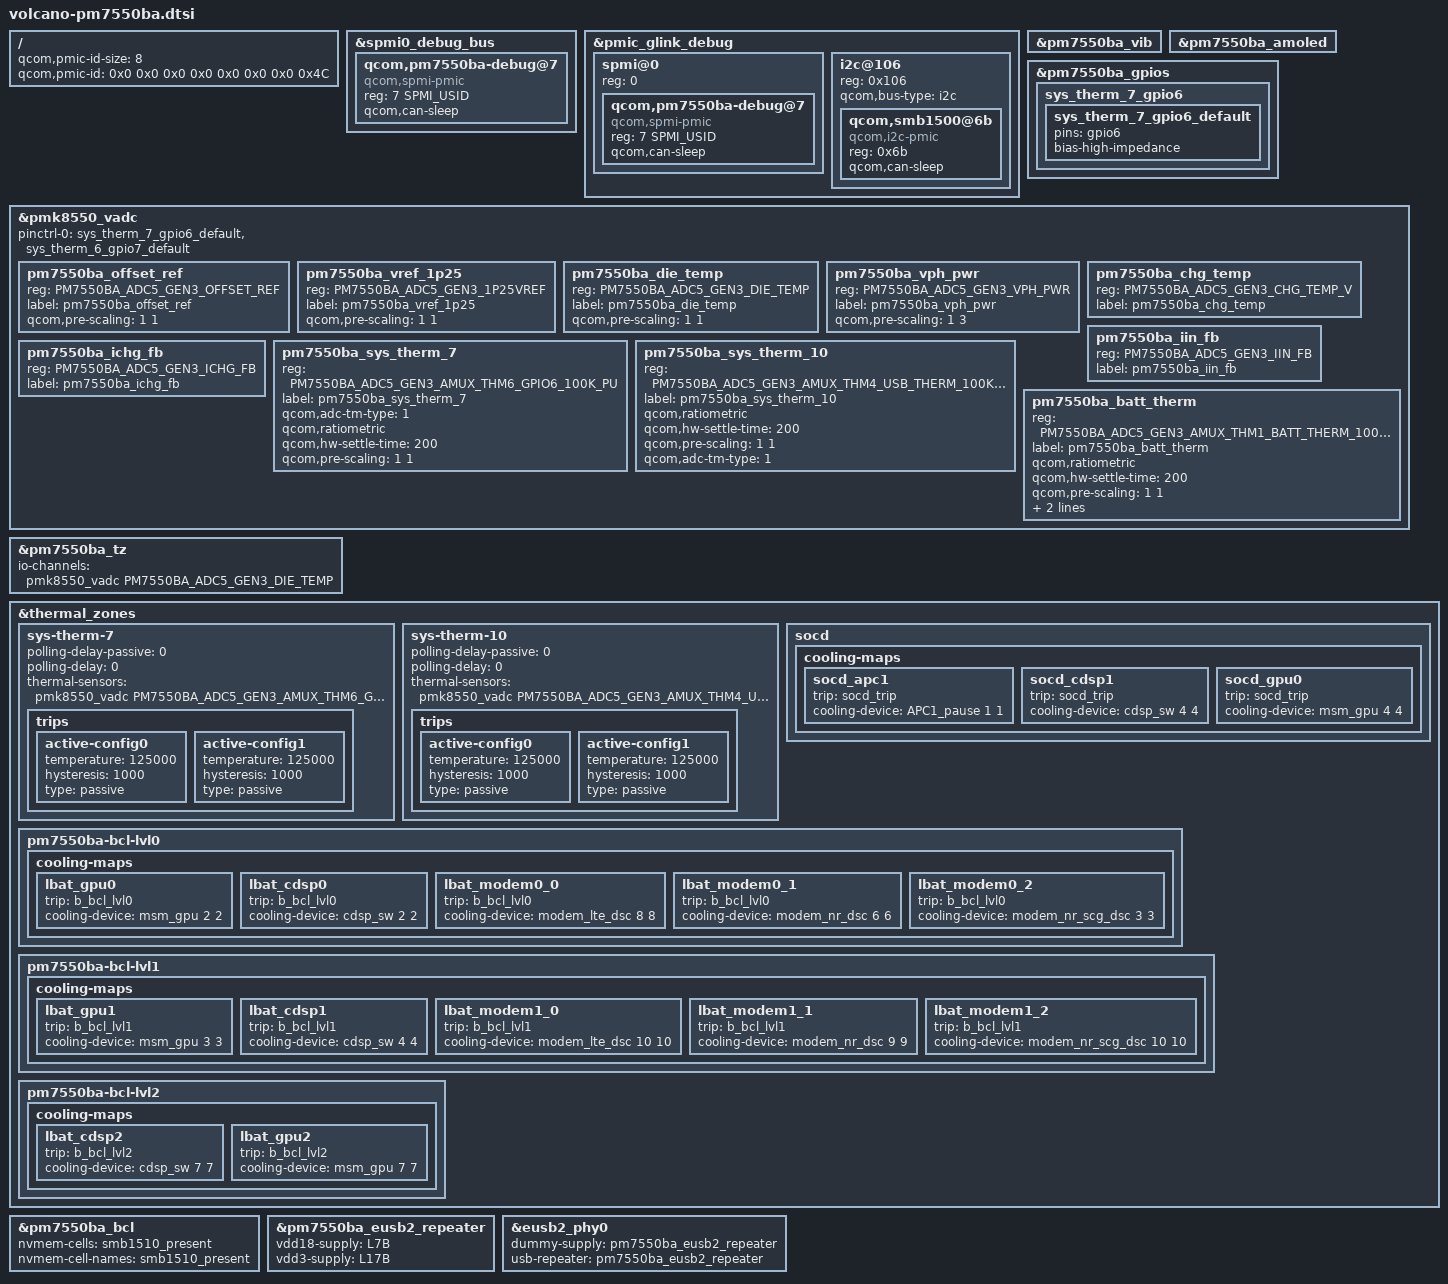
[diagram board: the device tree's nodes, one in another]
#include "pm7550ba.dtsi"
#include <dt-bindings/iio/qcom,spmi-vadc.h>
#include <dt-bindings/iio/qcom,spmi-adc5-gen3-pm7550ba.h>
#include <dt-bindings/spmi/spmi.h>

/ {
	qcom,pmic-id-size = <8>;
	qcom,pmic-id = <0x0 0x0 0x0 0x0 0x0 0x0 0x0 0x4C>;
};

&spmi0_debug_bus {
	qcom,pm7550ba-debug@7 {
		compatible = "qcom,spmi-pmic";
		reg = <7 SPMI_USID>;
		#address-cells = <2>;
		#size-cells = <0>;
		qcom,can-sleep;
	};
};

&pmic_glink_debug {
	/* Primary SPMI bus */
	spmi@0 {
		reg = <0>;
		#address-cells = <2>;
		#size-cells = <0>;

		qcom,pm7550ba-debug@7 {
			compatible = "qcom,spmi-pmic";
			reg = <7 SPMI_USID>;
			qcom,can-sleep;
		};
	};

	i2c@106 {
		reg = <0x106>;  /* I2C instance 6 in ADSP for SE7 */
		#address-cells = <1>;
		#size-cells = <0>;
		qcom,bus-type = "i2c";

		qcom,smb1500@6b {
			compatible = "qcom,i2c-pmic";
			reg = <0x6b>;
			qcom,can-sleep;
		};
	};
};

&pm7550ba_vib {
	status = "okay";
};

&pm7550ba_amoled {
	status = "okay";
};

&pm7550ba_gpios {
	sys_therm_7_gpio6 {
		sys_therm_7_gpio6_default: sys_therm_7_gpio6_default {
			pins = "gpio6";
			bias-high-impedance;
		};
	};
};

&pmk8550_vadc {
	pinctrl-0 = <&sys_therm_7_gpio6_default &sys_therm_6_gpio7_default>;
	pinctrl-names = "default";

	/* PM7550BA Channel nodes */
	pm7550ba_offset_ref {
		reg = <PM7550BA_ADC5_GEN3_OFFSET_REF>;
		label = "pm7550ba_offset_ref";
		qcom,pre-scaling = <1 1>;
	};

	pm7550ba_vref_1p25 {
		reg = <PM7550BA_ADC5_GEN3_1P25VREF>;
		label = "pm7550ba_vref_1p25";
		qcom,pre-scaling = <1 1>;
	};

	pm7550ba_die_temp {
		reg = <PM7550BA_ADC5_GEN3_DIE_TEMP>;
		label = "pm7550ba_die_temp";
		qcom,pre-scaling = <1 1>;
	};

	pm7550ba_vph_pwr {
		reg = <PM7550BA_ADC5_GEN3_VPH_PWR>;
		label = "pm7550ba_vph_pwr";
		qcom,pre-scaling = <1 3>;
	};

	pm7550ba_chg_temp {
		reg = <PM7550BA_ADC5_GEN3_CHG_TEMP_V>;
		label = "pm7550ba_chg_temp";
	};

	pm7550ba_iin_fb {
		reg = <PM7550BA_ADC5_GEN3_IIN_FB>;
		label = "pm7550ba_iin_fb";
	};

	pm7550ba_ichg_fb {
		reg = <PM7550BA_ADC5_GEN3_ICHG_FB>;
		label = "pm7550ba_ichg_fb";
	};

	pm7550ba_sys_therm_7 {
		reg = <PM7550BA_ADC5_GEN3_AMUX_THM6_GPIO6_100K_PU>;
		label = "pm7550ba_sys_therm_7";
		qcom,adc-tm-type = <1>;
		qcom,ratiometric;
		qcom,hw-settle-time = <200>;
		qcom,pre-scaling = <1 1>;
	};

	pm7550ba_sys_therm_10 {
		reg = <PM7550BA_ADC5_GEN3_AMUX_THM4_USB_THERM_100K_PU>;
		label = "pm7550ba_sys_therm_10";
		qcom,ratiometric;
		qcom,hw-settle-time = <200>;
		qcom,pre-scaling = <1 1>;
		qcom,adc-tm-type = <1>;

	};

	pm7550ba_batt_therm {
		reg = <PM7550BA_ADC5_GEN3_AMUX_THM1_BATT_THERM_100K_PU>;
		label = "pm7550ba_batt_therm";
		qcom,ratiometric;
		qcom,hw-settle-time = <200>;
		qcom,pre-scaling = <1 1>;
		qcom,scale-fn-type = <ADC_SCALE_HW_CALIB_PM5_GEN3_BATT_THERM_100K>;
	};

};

&pm7550ba_tz {
	io-channels = <&pmk8550_vadc PM7550BA_ADC5_GEN3_DIE_TEMP>;
	io-channel-names = "thermal";
};

&thermal_zones {
	sys-therm-7 {
		polling-delay-passive = <0>;
		polling-delay = <0>;
		thermal-sensors = <&pmk8550_vadc PM7550BA_ADC5_GEN3_AMUX_THM6_GPIO6_100K_PU>;
		trips {
			active-config0 {
				temperature = <125000>;
				hysteresis = <1000>;
				type = "passive";
			};

			active-config1 {
				temperature = <125000>;
				hysteresis = <1000>;
				type = "passive";
			};
		};
	};

	sys-therm-10 {
		polling-delay-passive = <0>;
		polling-delay = <0>;
		thermal-sensors = <&pmk8550_vadc PM7550BA_ADC5_GEN3_AMUX_THM4_USB_THERM_100K_PU>;
		trips {
			active-config0 {
				temperature = <125000>;
				hysteresis = <1000>;
				type = "passive";
			};

			active-config1 {
				temperature = <125000>;
				hysteresis = <1000>;
				type = "passive";
			};
		};
	};
};

&pm7550ba_bcl {
	nvmem-cells = <&smb1510_present>;
	nvmem-cell-names = "smb1510_present";
};

&thermal_zones {
	socd {
		cooling-maps {
			socd_apc1 {
				trip = <&socd_trip>;
				cooling-device = <&APC1_pause 1 1>;
			};

			socd_cdsp1 {
				trip = <&socd_trip>;
				cooling-device = <&cdsp_sw 4 4>;
			};

			socd_gpu0 {
				trip = <&socd_trip>;
				cooling-device = <&msm_gpu 4 4>;
			};
		};
	};

	pm7550ba-bcl-lvl0 {
		cooling-maps {
			lbat_gpu0 {
				trip = <&b_bcl_lvl0>;
				cooling-device = <&msm_gpu 2 2>;
			};

			lbat_cdsp0 {
				trip = <&b_bcl_lvl0>;
				cooling-device = <&cdsp_sw 2 2>;
			};

			lbat_modem0_0 {
				trip = <&b_bcl_lvl0>;
				cooling-device = <&modem_lte_dsc 8 8>;
			};

			lbat_modem0_1 {
				trip = <&b_bcl_lvl0>;
				cooling-device = <&modem_nr_dsc 6 6>;
			};

			lbat_modem0_2 {
				trip = <&b_bcl_lvl0>;
				cooling-device = <&modem_nr_scg_dsc 3 3>;
			};
		};
	};

	pm7550ba-bcl-lvl1 {
		cooling-maps {
			lbat_gpu1 {
				trip = <&b_bcl_lvl1>;
				cooling-device = <&msm_gpu 3 3>;
			};

			lbat_cdsp1 {
				trip = <&b_bcl_lvl1>;
				cooling-device = <&cdsp_sw 4 4>;
			};

			lbat_modem1_0 {
				trip = <&b_bcl_lvl1>;
				cooling-device = <&modem_lte_dsc 10 10>;
			};

			lbat_modem1_1 {
				trip = <&b_bcl_lvl1>;
				cooling-device = <&modem_nr_dsc 9 9>;
			};

			lbat_modem1_2 {
				trip = <&b_bcl_lvl1>;
				cooling-device = <&modem_nr_scg_dsc 10 10>;
			};
		};
	};

	pm7550ba-bcl-lvl2 {
		cooling-maps {
			lbat_cdsp2 {
				trip = <&b_bcl_lvl2>;
				cooling-device = <&cdsp_sw 7 7>;
			};

			lbat_gpu2 {
				trip = <&b_bcl_lvl2>;
				cooling-device = <&msm_gpu 7 7>;
			};
		};
	};
};

&pm7550ba_eusb2_repeater {
	status = "ok";
	vdd18-supply = <&L7B>;
	vdd3-supply = <&L17B>;
};

&eusb2_phy0 {
	dummy-supply = <&pm7550ba_eusb2_repeater>;
	usb-repeater = <&pm7550ba_eusb2_repeater>;
};
